# RL6845_IP_SVD register map
Vendor: Realtek
Registers are 32-bit, read-write, reset 0x0 unless marked. A register's access mark holds for its fields unless they carry their own. Offsets are from the block's base; [hi:lo] are bit positions; {n}, {i} and the like mark numbered series.

## RSIP_REG
Base 0x41104000
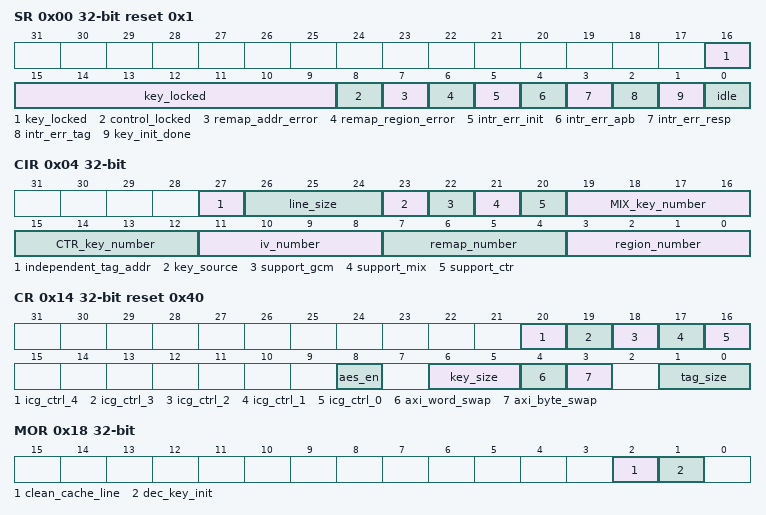
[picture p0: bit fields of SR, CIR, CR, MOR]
0x00 SR ro reset 0x1 — Status Register
  [16:9] key_locked — Indicate whether the keyx is locked. If it is locked, keyx cannot be written or read.
  [8] control_locked — Indicate whether the setting is locked. If it is locked, only ICR and MOR registers can be set.
  [7] remap_addr_error — Indicate the address after adding offset size cross 256MB boundaries.
  [6] remap_region_error — Indicate the read address hits multiple remapping region.
  [5] intr_err_init — Indicate the transaction was received before the key initialization is completed.
  [4] intr_err_apb — Indicate whether the setting configuration is failed. When a transaction is in progress, all settings except clear interruption are invalid.
  [3] intr_err_resp — Indicate an error response is received from slave.
  [2] intr_err_tag — Indicate a GCM tag mismatch error occurred.
  [1] key_init_done — Indicate whether the initialization of the key is completed. Only used in MIX mode.
  [0] idle — Indicate whether there is any outstanding transaction.
0x04 CIR ro — Component Identification Register
  [27] independent_tag_addr — Indicate the storage location of the tag 0: consecutive space - interleaved with each data blocks 1: separate space from data - use another base address
  [26:24] line_size — Cache line size 0: 16B = 1 AES block 1: 32B = 2 AES blocks 2: 64B = 4 AES blocks 3: 128B = 8 AES blocks Indicate how many 128-bit blocks are used to calculate the tag. cache line size (byte) = 16 * 2BLOCK_SIZE
  [23] key_source — Indicate the key source 0: from dedicated key port 1: from APB register
  [22] support_gcm — Indicate whether GCM mode is supported.
  [21] support_mix — Indicate whether MIX mode is supported.
  [20] support_ctr — Indicate whether CTR mode is supported.
  [19:16] MIX_key_number — Number of supported MIX key, valid when support_mix is 1.
  [15:12] CTR_key_number — Number of supported CTR key, valid when SUPPORT_CTR or SUPPORT_GCM is 1.
  [11:8] iv_number — Number of supported Ivs
  [7:4] remap_number — Number of supported remap regions
  [3:0] region_number — Number of supported decryption regions
0x08 EALR ro — Error Address Log Register
  [31:0] error_address — Recorded address when GCM tag mismatch error or receiving an error response.
0x10 ICR wo — Interrupt Clear Register
  [0] clr_intr — Interrupt clear It has to write 1'b1 to this register every time when the error exception occurs.
0x14 CR reset 0x40 — Control Register
  [20] icg_ctrl_4 — Disable key-reg auto clock-gating
  [19] icg_ctrl_3 — Disable APB-ctrl auto clock-gating
  [18] icg_ctrl_2 — Disable AES-engine auto clock-gating
  [17] icg_ctrl_1 — Disable fetch-unit auto clock-gating
  [16] icg_ctrl_0 — Disable line-buffer auto clock-gating
  [8] aes_en — Determine whether to enable the AES engine. 0: disable decryption engine (expect remapping function) 1: enable decryption engine and line buffer
  [6:5] key_size — Determine the size of key 0: 128 bits 1: 192 bits 2: 256 bits
  [4] axi_word_swap — Determine the endian of ciphertext in slave memory. Setting to 1 can swap word order.
  [3] axi_byte_swap — Determine the endian of ciphertext in slave memory. Setting to 1 can swap byte order.
  [1:0] tag_size — Tag size The size of the tag will affect the length of each tag command. 0: 32 bits 1: 64 bits 2: 128 bits
0x18 MOR wo — Maintenance Operation Register
  [2] clean_cache_line — Manually clear the line buffer. Write 1 to clear all after flash data update.
  [1] dec_key_init — Only used in MIX mode. Whenever the key is changed, write 1 to this bit to initialize the decryption key. When keys are updated by external port, SEC engine will trigger this bit automatically. The status of completion can be determined by reading bit 1 of the status register.
0x1C LR wo — Lock Register
  [7:0] lock_control — When setting 0xDC to this field, all registers except ICR, MOR and keys are not allowed to be written. Once the lock is set, the way to unlock is reset the flash SEC engine. If SW wants to modify the setting of control registers, it should keep this lock unset.
0x20 TBAR — GCM Tag Base Address Register
  [31:0] tag_base_0 — Tag base address for reference to the flash SEC engine. Not equal to actual tag address, need to be calculated. tag_base = tag_addr - (gcm_region_addr/number_of_byte_per_line) * number_of_byte_per_tag
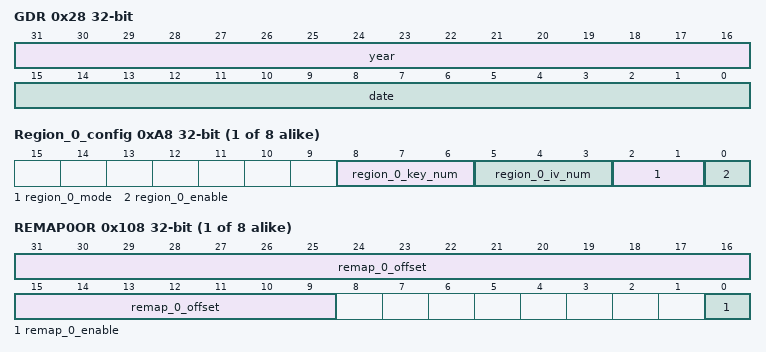
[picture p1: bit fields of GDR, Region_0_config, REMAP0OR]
0x28 GDR ro — Gen Date Register
  [31:16] year — Year of code generation
  [15:0] date — Date of code generation
0x2C VR ro — Version Register
  [31:0] version — Version of code generation
{0x30+4i} Lock_key{i} wo (i=0..7)
  [7:0] lock_key{i} — When setting 0xDC to this field, keyx are not allowed to be written or read. Once the lock is set, the way to unlock is reset the flash SEC engine. If SW wants to modify the key registers, it should keep this lock unset.
{0xA0+0xC*i} Region_{i}_base (i=0..7) — Region {i} base address register
  [31:5] region_{i}_base
{0xA4+0xC*i} Region_{i}_end (i=0..7) — Region {i} end address register
  [31:5] region_{i}_end
{0xA8+0xC*i} Region_{i}_config (i=0..7) — Region {i} setting register
  [8:6] region_{i}_key_num — Key used in region {i} Apply which key register to this region Number corresponds to key register
  [5:3] region_{i}_iv_num — IV used in region {i} Apply which IV register to this region Number corresponds to IV register
  [2:1] region_{i}_mode — Mode used in region {i} 2'b00: GCM mode 2'b01: CTR mode 2'b10: MIX mode 2'b11: Reserved
  [0] region_{i}_enable — Enable region {i} setting
{0x100+0xC*i} REMAP{i}BAR (i=0..7) — Remap {i} region base address register
  [31:9] remap_base_{i}_addr — Remap region {i} base address [27:5] Region_Base_Addr = {flash_base[31:28], remap_base_x_addr, {5{1'b0}} } The region address is configurable, and not cross 256KB.
{0x104+0xC*i} REMAP{i}EAR (i=0..7) — Remap {i} region end address register
  [31:9] remap_end_{i}_addr — Remap region {i} end address [27:5] Region_End_Addr = {flash_base[31:28], remap_end_{i}_addr, {5{1'b0}} } The region address is configurable, and not cross 256KB.
{0x108+0xC*i} REMAP{i}OR (i=0..7) — Remap {i} offset register
  [31:9] remap_{i}_offset — Remap region {i} offset [27:5] Region_Offset = {4'b0,remap_{i}_offset, {5{1'b0}}} The output address is "Access address - Region_Base_Addr + Region_Offset".
  [0] remap_{i}_enable — Remap region {i} enable
{0x200+0x20*i} Key{i}_0 (i=0..7) — Key{i} Register Bit[31:0]
  [31:0] key{i}_0 — Key{i} register bit[31:0] CTR of MIX, GCM, CTR mode using the key
{0x204+0x20*i} Key{i}_1 (i=0..7) — Key{i} Register Bit[63:32]
  [31:0] key{i}_1 — Key{i} register bit[63:32] CTR of MIX, GCM, CTR mode using the key
{0x208+0x20*i} Key{i}_2 (i=0..7) — Key{i} Register Bit[95:64]
  [31:0] key{i}_2 — Key{i} register bit[95:64] CTR of MIX, GCM, CTR mode using the key
{0x20C+0x20*i} Key{i}_3 (i=0..7) — Key{i} Register Bit[127:96]
  [31:0] key{i}_3 — Key{i} register bit[127:96] CTR of MIX, GCM, CTR mode using the key
{0x210+0x20*i} Key{i}_4 (i=0..7) — Key{i} Register Bit[159:128]
  [31:0] key{i}_4 — Key{i} register bit[159:128] CTR of MIX, GCM, CTR mode using the key
{0x214+0x20*i} Key{i}_5 (i=0..7) — Key{i} Register Bit[191:160]
  [31:0] key{i}_5 — Key{i} register bit[191:160] CTR of MIX, GCM, CTR mode using the key
{0x218+0x20*i} Key{i}_6 (i=0..7) — Key{i} Register Bit[223:192]
  [31:0] key{i}_6 — Key{i} register bit[223:192] CTR of MIX, GCM, CTR mode using the key
{0x21C+0x20*i} Key{i}_7 (i=0..7) — Key{i} Register Bit[255:224]
  [31:0] key{i}_7 — Key{i} register bit[255:224] CTR of MIX, GCM, CTR mode using the key
